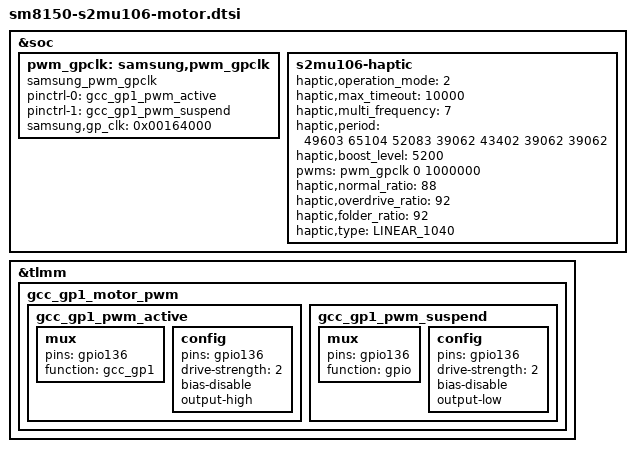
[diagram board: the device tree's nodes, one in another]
/* Copyright (c) 2016-2017, The Linux Foundation. All rights reserved.
 *
 * This program is free software; you can redistribute it and/or modify
 * it under the terms of the GNU General Public License version 2 and
 * only version 2 as published by the Free Software Foundation.
 *
 * This program is distributed in the hope that it will be useful,
 * but WITHOUT ANY WARRANTY; without even the implied warranty of
 * MERCHANTABILITY or FITNESS FOR A PARTICULAR PURPOSE.  See the
 * GNU General Public License for more details.
 */

&soc {
	pwm_gpclk: samsung,pwm_gpclk{
		#pwm-cells = <2>;
		compatible = "samsung_pwm_gpclk";
		pinctrl-names = "tlmm_motor_active","tlmm_motor_suspend";
		pinctrl-0 = <&gcc_gp1_pwm_active>;
		pinctrl-1 = <&gcc_gp1_pwm_suspend>;
		samsung,gp_clk = <0x00164000>;	// Address of GP1 clock
		status = "ok";
	};

	s2mu106-haptic {
		haptic,operation_mode = <2>; /* 0 : ERM_I2C, 1 : ERM_GPIO, 2 : LRA */
		haptic,max_timeout = <10000>;
		haptic,multi_frequency = <7>;
		/* frequency     alert low   mid   high  0     press release */
		haptic,period = <49603 65104 52083 39062 43402 39062 39062>;
		haptic,boost_level = <5200>;
		pwms = <&pwm_gpclk 0 1000000>;
		haptic,normal_ratio = <88>;
		haptic,overdrive_ratio = <92>;
		haptic,folder_ratio = <92>;
		haptic,type = "LINEAR_1040";
		status = "ok";
	};
};

&tlmm {
	gcc_gp1_motor_pwm {
		gcc_gp1_pwm_active: gcc_gp1_pwm_active {
			mux {
				pins = "gpio136";
				function = "gcc_gp1";
			};
			config {
				pins = "gpio136";
				drive-strength = <2>;   /* 16 mA */
				bias-disable;
				output-high;
			};
		};
		gcc_gp1_pwm_suspend: gcc_gp1_pwm_suspend {
			mux {
				pins = "gpio136";
				function = "gpio";
			};
			config {
				pins = "gpio136";
				drive-strength = <2>;   /* 16 mA */
				bias-disable;
				output-low;
			};
		};
	};
};
